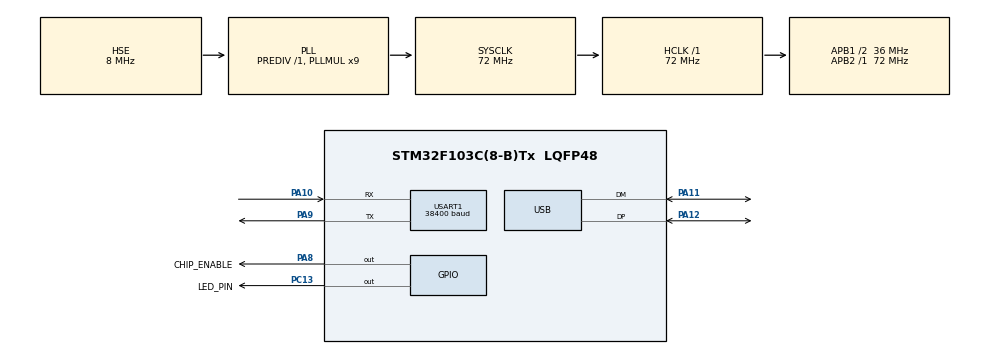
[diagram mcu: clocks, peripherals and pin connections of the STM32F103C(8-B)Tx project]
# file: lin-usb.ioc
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Mcu.Family=STM32F1
Mcu.Name=STM32F103C(8-B)Tx
Mcu.Package=LQFP48
NVIC.PriorityGroup=NVIC_PRIORITYGROUP_4
NVIC.USART1_IRQn=true\:0\:0\:false
NVIC.USB_LP_CAN1_RX0_IRQn=true\:0\:0\:false
PA10.Mode=LIN
PA10.Signal=USART1_RX
PA11.Mode=Device
PA11.Signal=USB_DM
PA12.Mode=Device
PA12.Signal=USB_DP
PA13.Mode=Serial_Wire
PA13.Signal=SYS_JTMS-SWDIO
PA14.Mode=Serial_Wire
PA14.Signal=SYS_JTCK-SWCLK
PA8.GPIO_Label=CHIP_ENABLE
PA8.Signal=GPIO_Output
PA9.Mode=LIN
PA9.Signal=USART1_TX
PC13-TAMPER-RTC.GPIO_Label=LED_PIN
PC13-TAMPER-RTC.Signal=GPIO_Output
PD0-OSC_IN.Mode=HSE-External-Oscillator
PD0-OSC_IN.Signal=RCC_OSC_IN
PD1-OSC_OUT.Mode=HSE-External-Oscillator
PD1-OSC_OUT.Signal=RCC_OSC_OUT
ProjectManager.TargetToolchain=MDK-ARM V5
RCC.AHBFreq_Value=72000000
RCC.APB1CLKDivider=RCC_HCLK_DIV2
RCC.APB1Freq_Value=36000000
RCC.APB1TimFreq_Value=72000000
RCC.APB2Freq_Value=72000000
RCC.APB2TimFreq_Value=72000000
RCC.HCLKFreq_Value=72000000
RCC.HSIState=RCC_HSI_ON
RCC.PLLMUL=RCC_PLL_MUL9
RCC.SYSCLKFreq_VALUE=72000000
RCC.SYSCLKSource=RCC_SYSCLKSOURCE_PLLCLK
RCC.USBFreq_Value=48000000
RCC.USBPrescaler=RCC_USBPLLCLK_DIV1_5
USART1.BaudRate=38400
USB_DEVICE.USBD_HandleTypeDef=hUsbDeviceFS
USB_DEVICE.USBD_MAX_STR_DESC_SIZ=64
USB_DEVICE.VirtualMode=Cdc
USB_DEVICE.VirtualModeFS=Cdc_FS
VP_USB_DEVICE_VS_USB_DEVICE_CDC_FS.Mode=CDC_FS
board=lin-usb

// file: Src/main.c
/**
  ******************************************************************************
  * File Name          : main.c
  * Description        : Main program body
  ******************************************************************************
  *
  * COPYRIGHT(c) 2016 STMicroelectronics
  *
  * Redistribution and use in source and binary forms, with or without modification,
  * are permitted provided that the following conditions are met:
  *   1. Redistributions of source code must retain the above copyright notice,
  *      this list of conditions and the following disclaimer.
  *   2. Redistributions in binary form must reproduce the above copyright notice,
  *      this list of conditions and the following disclaimer in the documentation
  *      and/or other materials provided with the distribution.
  *   3. Neither the name of STMicroelectronics nor the names of its contributors
  *      may be used to endorse or promote products derived from this software
  *      without specific prior written permission.
  *
  * THIS SOFTWARE IS PROVIDED BY THE COPYRIGHT HOLDERS AND CONTRIBUTORS "AS IS"
  * AND ANY EXPRESS OR IMPLIED WARRANTIES, INCLUDING, BUT NOT LIMITED TO, THE
  * IMPLIED WARRANTIES OF MERCHANTABILITY AND FITNESS FOR A PARTICULAR PURPOSE ARE
  * DISCLAIMED. IN NO EVENT SHALL THE COPYRIGHT HOLDER OR CONTRIBUTORS BE LIABLE
  * FOR ANY DIRECT, INDIRECT, INCIDENTAL, SPECIAL, EXEMPLARY, OR CONSEQUENTIAL
  * DAMAGES (INCLUDING, BUT NOT LIMITED TO, PROCUREMENT OF SUBSTITUTE GOODS OR
  * SERVICES; LOSS OF USE, DATA, OR PROFITS; OR BUSINESS INTERRUPTION) HOWEVER
  * CAUSED AND ON ANY THEORY OF LIABILITY, WHETHER IN CONTRACT, STRICT LIABILITY,
  * OR TORT (INCLUDING NEGLIGENCE OR OTHERWISE) ARISING IN ANY WAY OUT OF THE USE
  * OF THIS SOFTWARE, EVEN IF ADVISED OF THE POSSIBILITY OF SUCH DAMAGE.
  *
  ******************************************************************************
  */
#include "stm32f1xx_hal.h"
#include "usart.h"
#include "usb_device.h"
#include "gpio.h"

/* USER CODE BEGIN Includes */
#include "lin.h"
#include "usbd_cdc_if.h"
/* USER CODE END Includes */

/* USER CODE BEGIN PV */
/* Private variables ---------------------------------------------------------*/
uint8_t txBuff[3] = {0x11, 0x12, 0x13};

extern uint8_t rxBuff[64];
extern uint8_t commStatus;
LIN_FRAME_t txFrame;
LIN_FRAME_t rxFrame;
LIN_ERR_t check;
/* USER CODE END PV */

void SystemClock_Config(void);

/* USER CODE BEGIN PFP */
/* Private function prototypes -----------------------------------------------*/

/* USER CODE END PFP */

int main(void)
{

  /* USER CODE BEGIN 1 */
  //

  /* USER CODE END 1 */

  /* MCU Configuration----------------------------------------------------------*/

  /* Reset of all peripherals, Initializes the Flash interface and the Systick. */
  HAL_Init();

  /* Configure the system clock */
  SystemClock_Config();

  /* Initialize all configured peripherals */
  MX_GPIO_Init();
  MX_USART1_UART_Init();
  MX_USB_DEVICE_Init();

  /* USER CODE BEGIN 2 */
  UB_LIN_Master_Init();
  /* USER CODE END 2 */

  /* Infinite loop */
  /* USER CODE BEGIN WHILE */
  //HAL_Delay(1000);

 // HAL_UART_Receive_IT(&huart1, linRxBff, sizeof(linRxBff));

  while (1)
  {
  /* USER CODE END WHILE */

  /* USER CODE BEGIN 3 */
   // txFrame.frame_id=0x01;
  // txFrame.data_len=2;
  // txFrame.data[0]=0xA1;
   ///txFrame.data[1]=0xB2;
  //  LIN_SendData(&txFrame);
  // HAL_UART_Transmit(&huart1, txBuff, 1, 100);
  // huart1.Instance->DR = 0xAA;
   // HAL_Delay(500);
  /*  if(farmeBuffPtr > 0)
    {
      GetFrameFromBuff();
      CDC_Transmit_FS(txBuff, 3);
    }
    */
    //HAL_GPIO_TogglePin(LED_PIN_GPIO_Port, LED_PIN_Pin);
   // LIN_ReceiveData(&rxFrame);
  }
  /* USER CODE END 3 */

}

/** System Clock Configuration
*/
void SystemClock_Config(void)
{

  RCC_OscInitTypeDef RCC_OscInitStruct;
  RCC_ClkInitTypeDef RCC_ClkInitStruct;
  RCC_PeriphCLKInitTypeDef PeriphClkInit;

  RCC_OscInitStruct.OscillatorType = RCC_OSCILLATORTYPE_HSE;
  RCC_OscInitStruct.HSEState = RCC_HSE_ON;
  RCC_OscInitStruct.HSEPredivValue = RCC_HSE_PREDIV_DIV1;
  RCC_OscInitStruct.PLL.PLLState = RCC_PLL_ON;
  RCC_OscInitStruct.PLL.PLLSource = RCC_PLLSOURCE_HSE;
  RCC_OscInitStruct.PLL.PLLMUL = RCC_PLL_MUL9;
  HAL_RCC_OscConfig(&RCC_OscInitStruct);

  RCC_ClkInitStruct.ClockType = RCC_CLOCKTYPE_SYSCLK|RCC_CLOCKTYPE_PCLK1;
  RCC_ClkInitStruct.SYSCLKSource = RCC_SYSCLKSOURCE_PLLCLK;
  RCC_ClkInitStruct.AHBCLKDivider = RCC_SYSCLK_DIV1;
  RCC_ClkInitStruct.APB1CLKDivider = RCC_HCLK_DIV2;
  RCC_ClkInitStruct.APB2CLKDivider = RCC_HCLK_DIV1;
  HAL_RCC_ClockConfig(&RCC_ClkInitStruct, FLASH_LATENCY_2);

  PeriphClkInit.PeriphClockSelection = RCC_PERIPHCLK_USB;
  PeriphClkInit.UsbClockSelection = RCC_USBPLLCLK_DIV1_5;
  HAL_RCCEx_PeriphCLKConfig(&PeriphClkInit);

  HAL_SYSTICK_Config(HAL_RCC_GetHCLKFreq()/1000);

  HAL_SYSTICK_CLKSourceConfig(SYSTICK_CLKSOURCE_HCLK);

  /* SysTick_IRQn interrupt configuration */
  HAL_NVIC_SetPriority(SysTick_IRQn, 0, 0);
}

/************************ (C) COPYRIGHT STMicroelectronics *****END OF FILE****/
